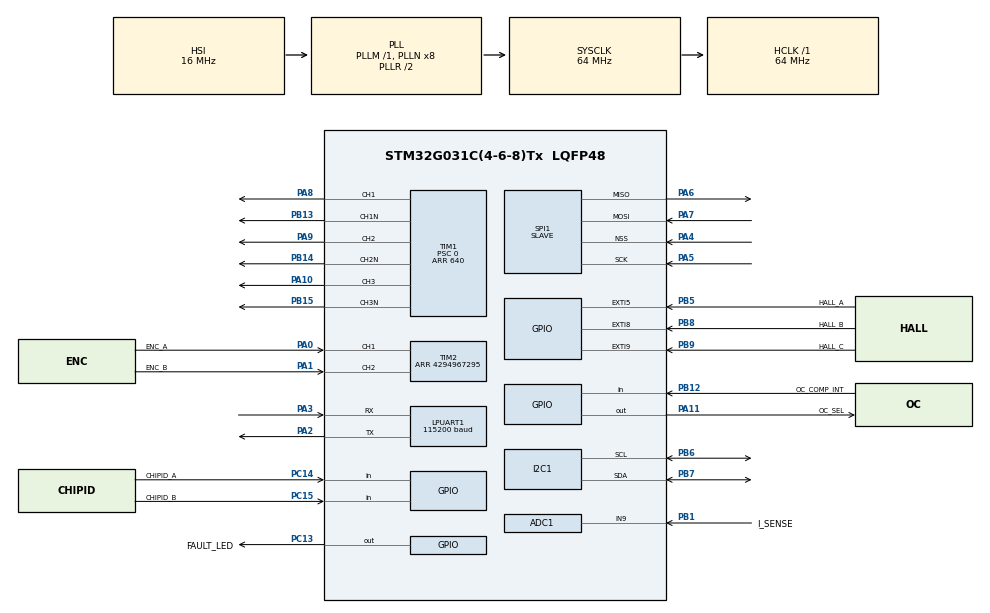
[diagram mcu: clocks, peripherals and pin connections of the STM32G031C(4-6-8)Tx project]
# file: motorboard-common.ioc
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ADC1.Channel-0\#ChannelRegularConversion=ADC_CHANNEL_9
ADC1.Channel-1\#ChannelRegularConversion=ADC_CHANNEL_TEMPSENSOR
ADC1.ClockPrescaler=ADC_CLOCK_SYNC_PCLK_DIV2
ADC1.ContinuousConvMode=DISABLE
ADC1.DMAContinuousRequests=ENABLE
ADC1.DiscontinuousConvMode=DISABLE
ADC1.ExternalTrigConv=ADC_EXTERNALTRIG_T1_CC4
ADC1.NbrOfConversion=2
ADC1.NbrOfConversionFlag=1
ADC1.Overrun=ADC_OVR_DATA_OVERWRITTEN
ADC1.OversamplingMode=DISABLE
ADC1.Rank-0\#ChannelRegularConversion=1
ADC1.Rank-1\#ChannelRegularConversion=2
ADC1.SamplingTime-0\#ChannelRegularConversion=ADC_SAMPLINGTIME_COMMON_2
ADC1.SamplingTime-1\#ChannelRegularConversion=ADC_SAMPLINGTIME_COMMON_1
ADC1.SamplingTimeCommon1=ADC_SAMPLETIME_160CYCLES_5
ADC1.SamplingTimeCommon2=ADC_SAMPLETIME_7CYCLES_5
ADC1.SelectedChannel=ADC_CHANNEL_TEMPSENSOR|ADC_CHANNEL_9
ADC1.master=1
Dma.ADC1.0.Direction=DMA_PERIPH_TO_MEMORY
Dma.ADC1.0.EventEnable=DISABLE
Dma.ADC1.0.Instance=DMA1_Channel1
Dma.ADC1.0.MemDataAlignment=DMA_MDATAALIGN_WORD
Dma.ADC1.0.MemInc=DMA_MINC_ENABLE
Dma.ADC1.0.Mode=DMA_CIRCULAR
Dma.ADC1.0.PeriphDataAlignment=DMA_PDATAALIGN_WORD
Dma.ADC1.0.PeriphInc=DMA_PINC_DISABLE
Dma.ADC1.0.Polarity=HAL_DMAMUX_REQ_GEN_RISING
Dma.ADC1.0.Priority=DMA_PRIORITY_LOW
Dma.ADC1.0.RequestNumber=1
Dma.ADC1.0.SignalID=NONE
Dma.ADC1.0.SyncEnable=DISABLE
Dma.ADC1.0.SyncPolarity=HAL_DMAMUX_SYNC_NO_EVENT
Dma.ADC1.0.SyncRequestNumber=1
Dma.ADC1.0.SyncSignalID=NONE
Dma.Request0=ADC1
LPUART1.BaudRate=115200
LPUART1.SwapParam=UART_ADVFEATURE_SWAP_ENABLE
LPUART1.WordLength=UART_WORDLENGTH_8B
Mcu.Family=STM32G0
Mcu.Name=STM32G031C(4-6-8)Tx
Mcu.Package=LQFP48
NVIC.DMA1_Channel1_IRQn=true\:0\:0\:false\:false\:true\:false\:true\:true
NVIC.EXTI4_15_IRQn=true\:0\:0\:true\:false\:true\:true\:true\:true
NVIC.TIM14_IRQn=true\:1\:0\:true\:false\:true\:true\:true\:true
NVIC.TIM16_IRQn=true\:2\:0\:true\:false\:true\:true\:true\:true
PA0.GPIO_Label=ENC_A
PA0.Signal=S_TIM2_CH1_ETR
PA1.GPIO_Label=ENC_B
PA1.Signal=S_TIM2_CH2
PA10.Signal=S_TIM1_CH3
PA11\ [PA9].GPIO_Label=OC_SEL
PA11\ [PA9].Signal=GPIO_Output
PA13.Mode=Serial_Wire
PA13.Signal=SYS_SWDIO
PA14-BOOT0.Mode=Serial_Wire
PA14-BOOT0.Signal=SYS_SWCLK
PA2.Mode=Asynchronous
PA2.Signal=LPUART1_TX
PA3.Mode=Asynchronous
PA3.Signal=LPUART1_RX
PA4.Mode=NSS_Signal_Hard_Input
PA4.Signal=SPI1_NSS
PA5.GPIO_Speed=GPIO_SPEED_FREQ_HIGH
PA5.Mode=Full_Duplex_Slave
PA5.Signal=SPI1_SCK
PA6.GPIO_Speed=GPIO_SPEED_FREQ_HIGH
PA6.Mode=Full_Duplex_Slave
PA6.Signal=SPI1_MISO
PA7.GPIO_Speed=GPIO_SPEED_FREQ_HIGH
PA7.Mode=Full_Duplex_Slave
PA7.Signal=SPI1_MOSI
PA8.Signal=S_TIM1_CH1
PA9.Signal=S_TIM1_CH2
PB1.GPIO_Label=I_SENSE
PB1.Mode=IN9
PB1.Signal=ADC1_IN9
PB12.GPIO_Label=OC_COMP_INT
PB12.Signal=GPIO_Input
PB13.Mode=PWM Generation1 CH1 CH1N
PB13.Signal=TIM1_CH1N
PB14.Mode=PWM Generation2 CH2 CH2N
PB14.Signal=TIM1_CH2N
PB15.Mode=PWM Generation3 CH3 CH3N
PB15.Signal=TIM1_CH3N
PB5.GPIO_Label=HALL_A
PB5.GPIO_ModeDefaultEXTI=GPIO_MODE_IT_RISING_FALLING
PB5.Signal=GPXTI5
PB6.Mode=I2C
PB6.Signal=I2C1_SCL
PB7.Mode=I2C
PB7.Signal=I2C1_SDA
PB8.GPIO_Label=HALL_B
PB8.GPIO_ModeDefaultEXTI=GPIO_MODE_IT_RISING_FALLING
PB8.Signal=GPXTI8
PB9.GPIO_Label=HALL_C
PB9.GPIO_ModeDefaultEXTI=GPIO_MODE_IT_RISING_FALLING
PB9.Signal=GPXTI9
PC13.GPIO_Label=FAULT_LED
PC13.Signal=GPIO_Output
PC14-OSC32_IN\ (PC14).GPIO_Label=CHIPID_A
PC14-OSC32_IN\ (PC14).Signal=GPIO_Input
PC15-OSC32_OUT\ (PC15).GPIO_Label=CHIPID_B
PC15-OSC32_OUT\ (PC15).Signal=GPIO_Input
ProjectManager.HeapSize=0x200
ProjectManager.StackSize=0x400
ProjectManager.TargetToolchain=CMake
RCC.ADCFreq_Value=64000000
RCC.AHBFreq_Value=64000000
RCC.CortexFreq_Value=64000000
RCC.EXTERNAL_CLOCK_VALUE=12288000
RCC.HCLKFreq_Value=64000000
RCC.HSE_VALUE=8000000
RCC.HSI_VALUE=16000000
RCC.LSE_VALUE=32768
RCC.SYSCLKFreq_VALUE=64000000
RCC.SYSCLKSource=RCC_SYSCLKSOURCE_PLLCLK
RCC.VCOOutputFreq_Value=128000000
SH.S_TIM1_CH1.0=TIM1_CH1,PWM Generation1 CH1 CH1N
SH.S_TIM1_CH2.0=TIM1_CH2,PWM Generation2 CH2 CH2N
SH.S_TIM1_CH3.0=TIM1_CH3,PWM Generation3 CH3 CH3N
SH.S_TIM2_CH1_ETR.0=TIM2_CH1,Encoder_Interface
SH.S_TIM2_CH2.0=TIM2_CH2,Encoder_Interface
SPI1.DataSize=SPI_DATASIZE_8BIT
SPI1.Direction=SPI_DIRECTION_2LINES
SPI1.Mode=SPI_MODE_SLAVE
SPI1.TIMode=SPI_TIMODE_DISABLE
SPI1.VirtualNSS=VM_NSSHARD
SPI1.VirtualType=VM_SLAVE
TIM1.AutoReloadPreload=TIM_AUTORELOAD_PRELOAD_ENABLE
TIM1.AutomaticOutput=TIM_AUTOMATICOUTPUT_ENABLE
TIM1.BreakState=TIM_BREAK_ENABLE
TIM1.Channel-PWM\ Generation1\ CH1\ CH1N=TIM_CHANNEL_1
TIM1.Channel-PWM\ Generation2\ CH2\ CH2N=TIM_CHANNEL_2
TIM1.Channel-PWM\ Generation3\ CH3\ CH3N=TIM_CHANNEL_3
TIM1.Channel-PWM\ Generation4\ No\ Output=TIM_CHANNEL_4
TIM1.CounterMode=TIM_COUNTERMODE_CENTERALIGNED1
TIM1.DeadTime=10
TIM1.OCMode_PWM-PWM\ Generation4\ No\ Output=TIM_OCMODE_PWM1
TIM1.OffStateIDLEMode=TIM_OSSI_ENABLE
TIM1.OffStateRunMode=TIM_OSSR_ENABLE
TIM1.Period=640
TIM1.Prescaler=0
TIM1.Pulse-PWM\ Generation4\ No\ Output=10
TIM14.AutoReloadPreload=TIM_AUTORELOAD_PRELOAD_ENABLE
TIM14.Period=16000
TIM16.AutoReloadPreload=TIM_AUTORELOAD_PRELOAD_ENABLE
TIM16.Period=64000
TIM2.AutoReloadPreload=TIM_AUTORELOAD_PRELOAD_ENABLE
TIM2.Period=4294967295
VP_ADC1_TempSens_Input.Mode=IN-TempSens
VP_SYS_V_PVD_IN.Mode=Mode_PVD_Int
VP_TIM14_VS_ClockSourceINT.Mode=Enable_Timer
VP_TIM16_VS_ClockSourceINT.Mode=Enable_Timer
VP_TIM1_VS_ClockSourceINT.Mode=Internal
VP_TIM1_VS_no_output4.Mode=PWM Generation4 No Output
board=custom

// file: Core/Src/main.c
/* USER CODE BEGIN Header */
/**
 ******************************************************************************
 * @file           : main.c
 * @brief          : Main program body
 ******************************************************************************
 * @attention
 *
 * Copyright (c) 2026 STMicroelectronics.
 * All rights reserved.
 *
 * This software is licensed under terms that can be found in the LICENSE file
 * in the root directory of this software component.
 * If no LICENSE file comes with this software, it is provided AS-IS.
 *
 ******************************************************************************
 */
/* USER CODE END Header */
#include "main.h"
#include "adc.h"
#include "dma.h"
#include "i2c.h"
#include "usart.h"
#include "spi.h"
#include "tim.h"
#include "gpio.h"

/* USER CODE BEGIN Includes */
#include "app.h"
/* USER CODE END Includes */

void SystemClock_Config(void);

int main(void)
{

  /* MCU Configuration--------------------------------------------------------*/

  /* Reset of all peripherals, Initializes the Flash interface and the Systick. */
  HAL_Init();

  /* Configure the system clock */
  SystemClock_Config();

  /* Initialize all configured peripherals */
  MX_GPIO_Init();
  MX_DMA_Init();
  MX_ADC1_Init();
  MX_I2C1_Init();
  MX_LPUART1_UART_Init();
  MX_SPI1_Init();
  MX_TIM1_Init();
  MX_TIM2_Init();
  MX_TIM14_Init();
  MX_TIM16_Init();

  /* Infinite loop */
  while (1) {

    /* USER CODE BEGIN 3 */
    app_start();
  }
  /* USER CODE END 3 */
}

void SystemClock_Config(void)
{
  RCC_OscInitTypeDef RCC_OscInitStruct = {0};
  RCC_ClkInitTypeDef RCC_ClkInitStruct = {0};

  /** Configure the main internal regulator output voltage
  */
  HAL_PWREx_ControlVoltageScaling(PWR_REGULATOR_VOLTAGE_SCALE1);

  /** Initializes the RCC Oscillators according to the specified parameters
  * in the RCC_OscInitTypeDef structure.
  */
  RCC_OscInitStruct.OscillatorType = RCC_OSCILLATORTYPE_HSI;
  RCC_OscInitStruct.HSIState = RCC_HSI_ON;
  RCC_OscInitStruct.HSIDiv = RCC_HSI_DIV1;
  RCC_OscInitStruct.HSICalibrationValue = RCC_HSICALIBRATION_DEFAULT;
  RCC_OscInitStruct.PLL.PLLState = RCC_PLL_ON;
  RCC_OscInitStruct.PLL.PLLSource = RCC_PLLSOURCE_HSI;
  RCC_OscInitStruct.PLL.PLLM = RCC_PLLM_DIV1;
  RCC_OscInitStruct.PLL.PLLN = 8;
  RCC_OscInitStruct.PLL.PLLP = RCC_PLLP_DIV2;
  RCC_OscInitStruct.PLL.PLLQ = RCC_PLLQ_DIV2;
  RCC_OscInitStruct.PLL.PLLR = RCC_PLLR_DIV2;
  if (HAL_RCC_OscConfig(&RCC_OscInitStruct) != HAL_OK)
  {
    Error_Handler();
  }

  /** Initializes the CPU, AHB and APB buses clocks
  */
  RCC_ClkInitStruct.ClockType = RCC_CLOCKTYPE_HCLK|RCC_CLOCKTYPE_SYSCLK
                              |RCC_CLOCKTYPE_PCLK1;
  RCC_ClkInitStruct.SYSCLKSource = RCC_SYSCLKSOURCE_PLLCLK;
  RCC_ClkInitStruct.AHBCLKDivider = RCC_SYSCLK_DIV1;
  RCC_ClkInitStruct.APB1CLKDivider = RCC_HCLK_DIV1;

  if (HAL_RCC_ClockConfig(&RCC_ClkInitStruct, FLASH_LATENCY_2) != HAL_OK)
  {
    Error_Handler();
  }
}

void Error_Handler(void)
{
  __disable_irq();
  while (1) {
  }
}
#ifdef USE_FULL_ASSERT
/**
  * @brief  Reports the name of the source file and the source line number
  *         where the assert_param error has occurred.
  * @param  file: pointer to the source file name
  * @param  line: assert_param error line source number
  * @retval None
  */
void assert_failed(uint8_t *file, uint32_t line)
{
  /* USER CODE BEGIN 6 */
  /* User can add his own implementation to report the file name and line
     number, ex: printf("Wrong parameters value: file %s on line %d\r\n", file,
     line) */
  /* USER CODE END 6 */
}
#endif /* USE_FULL_ASSERT */
